# STM32H733 register map
File version: 1.8
CPU: CM7 r0p1, little endian, MPU, FPU, 4 interrupt priority bits
Registers are 32-bit, read-write, reset 0x0 unless marked. A register's access mark holds for its fields unless they carry their own. Offsets are from the block's base; [hi:lo] are bit positions.

## SWPMI — Single Wire Protocol Master Interface
Base 0x40008800
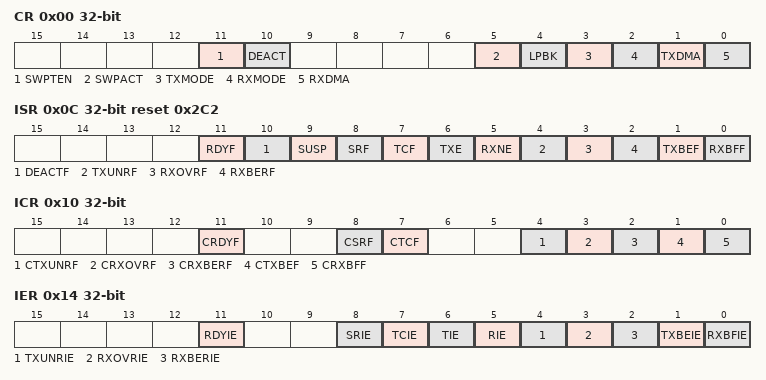
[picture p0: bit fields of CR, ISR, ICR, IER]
0x00 CR — SWPMI Configuration/Control register
  [11] SWPTEN — Single wire protocol master transceiver enable
  [10] DEACT — Single wire protocol master interface deactivate
  [5] SWPACT — Single wire protocol master interface activate
  [4] LPBK — Loopback mode enable
  [3] TXMODE — Transmission buffering mode
  [2] RXMODE — Reception buffering mode
  [1] TXDMA — Transmission DMA enable
  [0] RXDMA — Reception DMA enable
0x04 BRR reset 0x1 — SWPMI Bitrate register
  [7:0] BR — Bitrate prescaler
0x0C ISR ro reset 0x2C2 — SWPMI Interrupt and Status register
  [11] RDYF — transceiver ready flag
  [10] DEACTF — DEACTIVATED flag
  [9] SUSP — SUSPEND flag
  [8] SRF — Slave resume flag
  [7] TCF — Transfer complete flag
  [6] TXE — Transmit data register empty
  [5] RXNE — Receive data register not empty
  [4] TXUNRF — Transmit underrun error flag
  [3] RXOVRF — Receive overrun error flag
  [2] RXBERF — Receive CRC error flag
  [1] TXBEF — Transmit buffer empty flag
  [0] RXBFF — Receive buffer full flag
0x10 ICR wo — SWPMI Interrupt Flag Clear register
  [11] CRDYF — Clear transceiver ready flag
  [8] CSRF — Clear slave resume flag
  [7] CTCF — Clear transfer complete flag
  [4] CTXUNRF — Clear transmit underrun error flag
  [3] CRXOVRF — Clear receive overrun error flag
  [2] CRXBERF — Clear receive CRC error flag
  [1] CTXBEF — Clear transmit buffer empty flag
  [0] CRXBFF — Clear receive buffer full flag
0x14 IER — SWPMI Interrupt Enable register
  [11] RDYIE — Transceiver ready interrupt enable
  [8] SRIE — Slave resume interrupt enable
  [7] TCIE — Transmit complete interrupt enable
  [6] TIE — Transmit interrupt enable
  [5] RIE — Receive interrupt enable
  [4] TXUNRIE — Transmit underrun error interrupt enable
  [3] RXOVRIE — Receive overrun error interrupt enable
  [2] RXBERIE — Receive CRC error interrupt enable
  [1] TXBEIE — Transmit buffer empty interrupt enable
  [0] RXBFIE — Receive buffer full interrupt enable
0x18 RFL ro — SWPMI Receive Frame Length register
  [4:0] RFL — Receive frame length
0x1C TDR wo — SWPMI Transmit data register
  [31:0] TD — Transmit data
0x20 RDR ro — SWPMI Receive data register
  [31:0] RD — received data
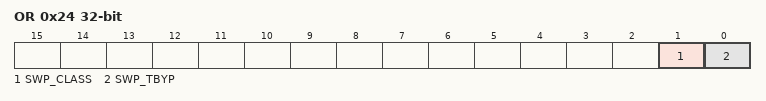
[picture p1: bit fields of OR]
0x24 OR — SWPMI Option register
  [1] SWP_CLASS — SWP class selection
  [0] SWP_TBYP — SWP transceiver bypass

## TIM6 — Basic timers
Base 0x40001000
Same registers: TIM7 0x40001400
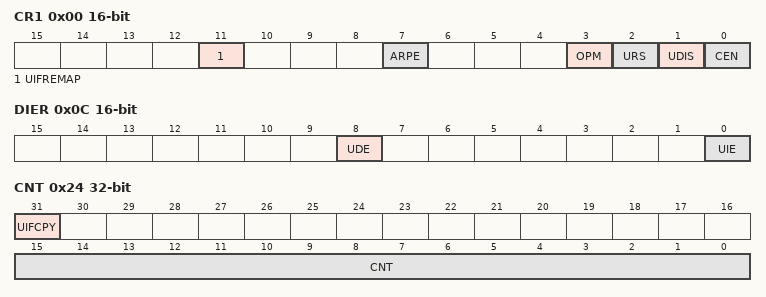
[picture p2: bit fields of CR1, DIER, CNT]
0x00 CR1 16-bit — control register 1
  [11] UIFREMAP — UIF status bit remapping
  [7] ARPE — Auto-reload preload enable
    0=Disabled (TIMx_APRR register is not buffered); 1=Enabled (TIMx_APRR register is buffered)
  [3] OPM — One-pulse mode
    0=Disabled (Counter is not stopped at update event); 1=Enabled (Counter stops counting at the next update event (clearing the CEN bit))
  [2] URS — Update request source
    0=AnyEvent (Any of counter overflow/underflow, setting UG, or update through slave mode, generates an update interrupt or DMA request); 1=CounterOnly (Only counter overflow/underflow generates an update interrupt or DMA request)
  [1] UDIS — Update disable
    0=Enabled (Update event enabled); 1=Disabled (Update event disabled)
  [0] CEN — Counter enable
    0=Disabled (Counter disabled); 1=Enabled (Counter enabled)
0x04 CR2 16-bit — control register 2
  [6:4] MMS — Master mode selection
    0=Reset (Use UG bit from TIMx_EGR register); 1=Enable (Use CNT bit from TIMx_CEN register); 2=Update (Use the update event)
0x0C DIER 16-bit — DMA/Interrupt enable register
  [8] UDE — Update DMA request enable
    0=Disabled (Update DMA request disabled); 1=Enabled (Update DMA request enabled)
  [0] UIE — Update interrupt enable
    0=Disabled (Update interrupt disabled); 1=Enabled (Update interrupt enabled)
0x10 SR 16-bit — status register
  [0] UIF write-0-clears — Update interrupt flag
    on read: 0=NoUpdateOccurred; 1=UpdatePending (Update interrupt pending) | on write: 0=Clear flag
0x14 EGR wo — event generation register
  [0] UG — Update generation
    1=Update (Re-initializes the timer counter and generates an update of the registers.)
0x24 CNT — counter
  [31] UIFCPY — UIF Copy
  [15:0] CNT — Low counter value
0x24 CNT16 16-bit (alternate view of CNT) — 16-bit counter register
  [15:0] CNT — counter value
0x28 PSC 16-bit — prescaler
  [15:0] PSC — Prescaler value
0x2C ARR 16-bit reset 0xFFFF — auto-reload register
  [15:0] ARR — Low Auto-reload value

## VREFBUF
Base 0x58003C00
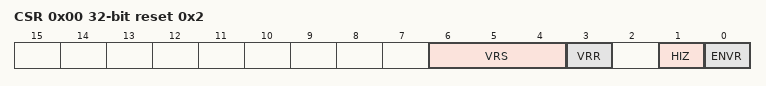
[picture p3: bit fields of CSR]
0x00 CSR access per field reset 0x2 — VREFBUF control and status register
  [6:4] VRS rw — Voltage reference scale These bits select the value generated by the voltage reference buffer. Other: Reserved
  [3] VRR ro — Voltage reference buffer ready
  [1] HIZ rw — High impedance mode This bit controls the analog switch to connect or not the VREF+ pin. Refer to Table196: VREF buffer modes for the mode descriptions depending on ENVR bit configuration.
  [0] ENVR rw — Voltage reference buffer mode enable This bit is used to enable the voltage reference buffer mode.
0x04 CCR — VREFBUF calibration control register
  [5:0] TRIM — Trimming code These bits are automatically initialized after reset with the trimming value stored in the Flash memory during the production test. Writing into these bits allows to tune the internal reference buffer voltage.

## WWDG1 — WWDG
Base 0x50003000
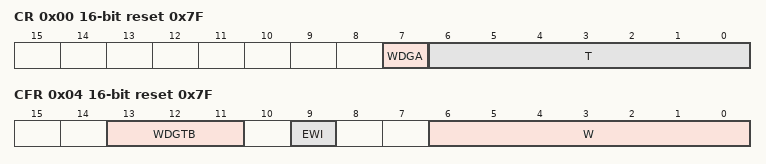
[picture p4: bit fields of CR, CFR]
0x00 CR 16-bit reset 0x7F — Control register
  [7] WDGA — Activation bit This bit is set by software and only cleared by hardware after a reset. When WDGA=1, the watchdog can generate a reset.
    0=Disabled (Watchdog disabled); 1=Enabled (Watchdog enabled)
  [6:0] T — 7-bit counter (MSB to LSB) These bits contain the value of the watchdog counter. It is decremented every (4096 x 2WDGTB[1:0]) PCLK cycles. A reset is produced when it is decremented from 0x40 to 0x3F (T6 becomes cleared).
0x04 CFR 16-bit reset 0x7F — Configuration register
  [13:11] WDGTB — Timer base The time base of the prescaler can be modified as follows:
    0=Div1 (Counter clock (PCLK1 div 4096) div 1); 1=Div2 (Counter clock (PCLK1 div 4096) div 2); 2=Div4 (Counter clock (PCLK1 div 4096) div 4); 3=Div8 (Counter clock (PCLK1 div 4096) div 8); 4=Div16 (Counter clock (PCLK1 div 4096) div 16); 5=Div32 (Counter clock (PCLK1 div 4096) div 32); 6=Div64 (Counter clock (PCLK1 div 4096) div 64); 7=Div128 (Counter clock (PCLK1 div 4096) div 128)
  [9] EWI — Early wakeup interrupt When set, an interrupt occurs whenever the counter reaches the value 0x40. This interrupt is only cleared by hardware after a reset.
    on write: 1=Enable (interrupt occurs whenever the counter reaches the value 0x40)
  [6:0] W — 7-bit window value These bits contain the window value to be compared to the downcounter.
0x08 SR 16-bit — Status register
  [0] EWIF write-0-clears — Early wakeup interrupt flag This bit is set by hardware when the counter has reached the value 0x40. It must be cleared by software by writing 0. A write of 1 has no effect. This bit is also set if the interrupt is not enabled.
    on read: 0=Finished (The EWI Interrupt Service Routine has been serviced); 1=Pending (The EWI Interrupt Service Routine has been triggered) | on write: 0=Finished (The EWI Interrupt Service Routine has been serviced)
